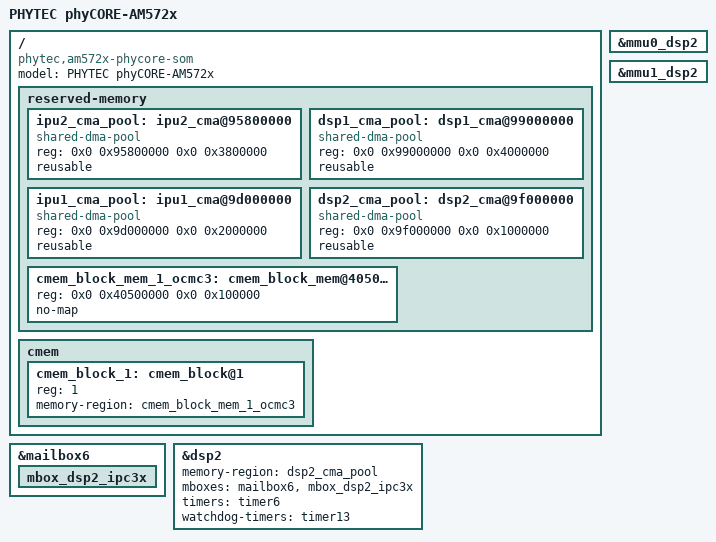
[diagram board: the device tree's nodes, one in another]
/*
 * Copyright (C) 2015 PHYTEC America, LLC. - www.phytec.com
 *
 * This program is free software; you can redistribute it and/or modify
 * it under the terms of the GNU General Public License version 2 as
 * published by the Free Software Foundation.
 */

#include "dra74x.dtsi"
#include <dt-bindings/gpio/gpio.h>
#include <dt-bindings/interrupt-controller/irq.h>
#include "am57xx-phycore-common.dtsi"

/ {
	model = "PHYTEC phyCORE-AM572x";
	compatible = "phytec,am572x-phycore-som", "ti,am5728", "ti,dra742", "ti,dra74", "ti,dra7";

	reserved-memory {
		#address-cells = <2>;
		#size-cells = <2>;
		ranges;

		ipu2_cma_pool: ipu2_cma@95800000 {
			compatible = "shared-dma-pool";
			reg = <0x0 0x95800000 0x0 0x3800000>;
			reusable;
			status = "okay";
		};

		dsp1_cma_pool: dsp1_cma@99000000 {
			compatible = "shared-dma-pool";
			reg = <0x0 0x99000000 0x0 0x4000000>;
			reusable;
			status = "okay";
		};

		ipu1_cma_pool: ipu1_cma@9d000000 {
			compatible = "shared-dma-pool";
			reg = <0x0 0x9d000000 0x0 0x2000000>;
			reusable;
			status = "okay";
		};

		dsp2_cma_pool: dsp2_cma@9f000000 {
			compatible = "shared-dma-pool";
			reg = <0x0 0x9f000000 0x0 0x1000000>;
			reusable;
			status = "okay";
		};

		cmem_block_mem_1_ocmc3: cmem_block_mem@40500000 {
			reg = <0x0 0x40500000 0x0 0x100000>;
			no-map;
			status = "okay";
		};
	};

	cmem {
		cmem_block_1: cmem_block@1 {
			reg = <1>;
			memory-region = <&cmem_block_mem_1_ocmc3>;
		};
	};
};

&mailbox6 {
	mbox_dsp2_ipc3x: mbox_dsp2_ipc3x {
		status = "okay";
	};
};

&mmu0_dsp2 {
	status = "okay";
};

&mmu1_dsp2 {
	status = "okay";
};

&dsp2 {
	status = "okay";
	memory-region = <&dsp2_cma_pool>;
	mboxes = <&mailbox6 &mbox_dsp2_ipc3x>;
	timers = <&timer6>;
	watchdog-timers = <&timer13>;
};
